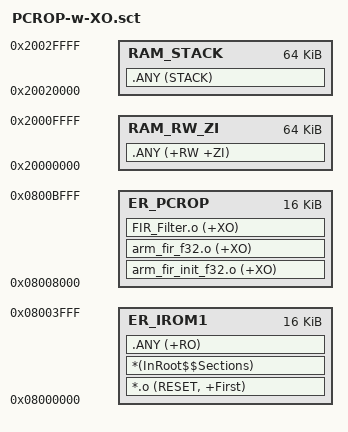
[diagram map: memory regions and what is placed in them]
; *************************************************************
; *** Scatter-Loading Description File generated by uVision ***
; *************************************************************

LR_IROM1 0x08000000 0x00004000  {    ; load region size_region
  ER_IROM1 0x08000000 0x00004000  {  ; load address = execution address
   *.o (RESET, +First)
   *(InRoot$$Sections)
   .ANY (+RO)
  }
  
  RAM_RW_ZI 0x20000000 0x00010000  {  ; RW data
   .ANY (+RW +ZI)
  }
  
  RAM_STACK 0x20020000 0x00010000  {  ; RW data
   .ANY (STACK)
  }
}

LR_PCROP 0x08008000 0x00004000  {
  ER_PCROP 0x08008000 0x00004000  {  ; load address = execution address
    
	arm_fir_init_f32.o (+XO)
	arm_fir_f32.o (+XO)
	FIR_Filter.o (+XO)
  }
}
